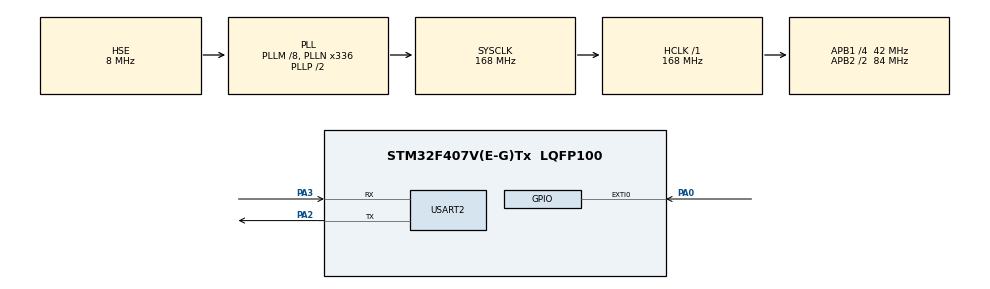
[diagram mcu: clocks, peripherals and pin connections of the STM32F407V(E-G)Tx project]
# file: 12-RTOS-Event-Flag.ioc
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FREERTOS.Tasks01=Task1,24,128,StartTask1,Default,NULL,Dynamic,NULL,NULL;Task02,24,128,StartTask02,Default,NULL,Dynamic,NULL,NULL;Task03,24,128,StartTask03,Default,NULL,Dynamic,NULL,NULL
Mcu.Family=STM32F4
Mcu.Name=STM32F407V(E-G)Tx
Mcu.Package=LQFP100
NVIC.EXTI0_IRQn=true\:5\:0\:true\:false\:true\:true\:true\:true\:true
NVIC.PriorityGroup=NVIC_PRIORITYGROUP_4
NVIC.TIM4_IRQn=true\:15\:0\:false\:false\:true\:false\:false\:true\:true
NVIC.TimeBase=TIM4_IRQn
NVIC.TimeBaseIP=TIM4
PA0-WKUP.Signal=GPXTI0
PA2.Mode=Asynchronous
PA2.Signal=USART2_TX
PA3.Mode=Asynchronous
PA3.Signal=USART2_RX
PH0-OSC_IN.Mode=HSE-External-Oscillator
PH0-OSC_IN.Signal=RCC_OSC_IN
PH1-OSC_OUT.Mode=HSE-External-Oscillator
PH1-OSC_OUT.Signal=RCC_OSC_OUT
ProjectManager.HeapSize=0x200
ProjectManager.StackSize=0x400
ProjectManager.TargetToolchain=STM32CubeIDE
RCC.48MHZClocksFreq_Value=48000000
RCC.AHBFreq_Value=168000000
RCC.APB1CLKDivider=RCC_HCLK_DIV4
RCC.APB1Freq_Value=42000000
RCC.APB1TimFreq_Value=84000000
RCC.APB2CLKDivider=RCC_HCLK_DIV2
RCC.APB2Freq_Value=84000000
RCC.APB2TimFreq_Value=168000000
RCC.CortexFreq_Value=168000000
RCC.HCLKFreq_Value=168000000
RCC.HSE_VALUE=8000000
RCC.HSI_VALUE=16000000
RCC.PLLM=8
RCC.PLLN=336
RCC.PLLQ=7
RCC.PLLSourceVirtual=RCC_PLLSOURCE_HSE
RCC.SYSCLKFreq_VALUE=168000000
RCC.SYSCLKSource=RCC_SYSCLKSOURCE_PLLCLK
RCC.VCOOutputFreq_Value=336000000
USART2.VirtualMode=VM_ASYNC
VP_FREERTOS_VS_CMSIS_V2.Mode=CMSIS_V2
VP_SYS_VS_tim4.Mode=TIM4
board=STM32F407G-DISC1

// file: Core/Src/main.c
/* USER CODE BEGIN Header */
/**
  ******************************************************************************
  * @file           : main.c
  * @brief          : Main program body
  ******************************************************************************
  * @attention
  *
  * Copyright (c) 2026 STMicroelectronics.
  * All rights reserved.
  *
  * This software is licensed under terms that can be found in the LICENSE file
  * in the root directory of this software component.
  * If no LICENSE file comes with this software, it is provided AS-IS.
  *
  ******************************************************************************
  */
/* USER CODE END Header */
#include "main.h"
#include "cmsis_os.h"

/* USER CODE BEGIN Includes */
#include "stdio.h"
#include "string.h"
/* USER CODE END Includes */

UART_HandleTypeDef huart2;

/* Definitions for Task1 */
osThreadId_t Task1Handle;
const osThreadAttr_t Task1_attributes = {
  .name = "Task1",
  .stack_size = 128 * 4,
  .priority = (osPriority_t) osPriorityNormal,
};
/* Definitions for Task02 */
osThreadId_t Task02Handle;
const osThreadAttr_t Task02_attributes = {
  .name = "Task02",
  .stack_size = 128 * 4,
  .priority = (osPriority_t) osPriorityNormal,
};
/* Definitions for Task03 */
osThreadId_t Task03Handle;
const osThreadAttr_t Task03_attributes = {
  .name = "Task03",
  .stack_size = 128 * 4,
  .priority = (osPriority_t) osPriorityNormal,
};
/* USER CODE BEGIN PV */
osEventFlagsId_t EventGroup;
/* USER CODE END PV */

void SystemClock_Config(void);
static void MX_GPIO_Init(void);
static void MX_USART2_UART_Init(void);
void StartTask1(void *argument);
void StartTask02(void *argument);
void StartTask03(void *argument);

/* USER CODE BEGIN 0 */
//int _write(int file, char *ptr, int len){
//	HAL_UART_Transmit(&huart2, (uint8_t*)ptr, len, HAL_MAX_DELAY);
//	return len;
//}

int _write(int file,char *ptr,int len)
{
	int i = 0;
	for(i=0;i<len;i++)
	{
		ITM_SendChar((*ptr++));
	}
	return len;
}
/* USER CODE END 0 */

int main(void)
{

  /* MCU Configuration--------------------------------------------------------*/

  /* Reset of all peripherals, Initializes the Flash interface and the Systick. */
  HAL_Init();

  /* Configure the system clock */
  SystemClock_Config();

  /* Initialize all configured peripherals */
  MX_GPIO_Init();
  MX_USART2_UART_Init();

  /* Init scheduler */
  osKernelInitialize();

  /* Create the thread(s) */
  /* creation of Task1 */
  Task1Handle = osThreadNew(StartTask1, NULL, &Task1_attributes);

  /* creation of Task02 */
  Task02Handle = osThreadNew(StartTask02, NULL, &Task02_attributes);

  /* creation of Task03 */
  Task03Handle = osThreadNew(StartTask03, NULL, &Task03_attributes);

  /* USER CODE BEGIN RTOS_THREADS */
  /* add threads, ... */
  EventGroup = osEventFlagsNew(NULL);
  /* USER CODE END RTOS_THREADS */

  /* Start scheduler */
  osKernelStart();

  /* We should never get here as control is now taken by the scheduler */

  /* Infinite loop */
  while (1)
  {

  }
}

void SystemClock_Config(void)
{
  RCC_OscInitTypeDef RCC_OscInitStruct = {0};
  RCC_ClkInitTypeDef RCC_ClkInitStruct = {0};

  /** Configure the main internal regulator output voltage
  */
  __HAL_RCC_PWR_CLK_ENABLE();
  __HAL_PWR_VOLTAGESCALING_CONFIG(PWR_REGULATOR_VOLTAGE_SCALE1);

  /** Initializes the RCC Oscillators according to the specified parameters
  * in the RCC_OscInitTypeDef structure.
  */
  RCC_OscInitStruct.OscillatorType = RCC_OSCILLATORTYPE_HSE;
  RCC_OscInitStruct.HSEState = RCC_HSE_ON;
  RCC_OscInitStruct.PLL.PLLState = RCC_PLL_ON;
  RCC_OscInitStruct.PLL.PLLSource = RCC_PLLSOURCE_HSE;
  RCC_OscInitStruct.PLL.PLLM = 8;
  RCC_OscInitStruct.PLL.PLLN = 336;
  RCC_OscInitStruct.PLL.PLLP = RCC_PLLP_DIV2;
  RCC_OscInitStruct.PLL.PLLQ = 7;
  if (HAL_RCC_OscConfig(&RCC_OscInitStruct) != HAL_OK)
  {
    Error_Handler();
  }

  /** Initializes the CPU, AHB and APB buses clocks
  */
  RCC_ClkInitStruct.ClockType = RCC_CLOCKTYPE_HCLK|RCC_CLOCKTYPE_SYSCLK
                              |RCC_CLOCKTYPE_PCLK1|RCC_CLOCKTYPE_PCLK2;
  RCC_ClkInitStruct.SYSCLKSource = RCC_SYSCLKSOURCE_PLLCLK;
  RCC_ClkInitStruct.AHBCLKDivider = RCC_SYSCLK_DIV1;
  RCC_ClkInitStruct.APB1CLKDivider = RCC_HCLK_DIV4;
  RCC_ClkInitStruct.APB2CLKDivider = RCC_HCLK_DIV2;

  if (HAL_RCC_ClockConfig(&RCC_ClkInitStruct, FLASH_LATENCY_5) != HAL_OK)
  {
    Error_Handler();
  }
}

static void MX_USART2_UART_Init(void)
{

  huart2.Instance = USART2;
  huart2.Init.BaudRate = 115200;
  huart2.Init.WordLength = UART_WORDLENGTH_8B;
  huart2.Init.StopBits = UART_STOPBITS_1;
  huart2.Init.Parity = UART_PARITY_NONE;
  huart2.Init.Mode = UART_MODE_TX_RX;
  huart2.Init.HwFlowCtl = UART_HWCONTROL_NONE;
  huart2.Init.OverSampling = UART_OVERSAMPLING_16;
  if (HAL_UART_Init(&huart2) != HAL_OK)
  {
    Error_Handler();
  }

}

static void MX_GPIO_Init(void)
{
  GPIO_InitTypeDef GPIO_InitStruct = {0};

  /* GPIO Ports Clock Enable */
  __HAL_RCC_GPIOH_CLK_ENABLE();
  __HAL_RCC_GPIOA_CLK_ENABLE();

  /*Configure GPIO pin : PA0 */
  GPIO_InitStruct.Pin = GPIO_PIN_0;
  GPIO_InitStruct.Mode = GPIO_MODE_IT_RISING;
  GPIO_InitStruct.Pull = GPIO_NOPULL;
  HAL_GPIO_Init(GPIOA, &GPIO_InitStruct);

  /* EXTI interrupt init*/
  HAL_NVIC_SetPriority(EXTI0_IRQn, 5, 0);
  HAL_NVIC_EnableIRQ(EXTI0_IRQn);

}

/* USER CODE BEGIN 4 */
void HAL_GPIO_EXIT_Callback(uint16_t GPIO_Pin){
	osEventFlagsSet(EventGroup, 0x50);
	printf("Task interrupt\n");
}
/* USER CODE END 4 */

void StartTask1(void *argument)
{
  /* USER CODE BEGIN 5 */
  /* Infinite loop */
  for(;;)
  {
	  osEventFlagsWait(EventGroup, 0x51, osFlagsWaitAll, osWaitForever);
	  printf("Task 1\n");
   // osDelay(1);
  }
  /* USER CODE END 5 */
}

void StartTask02(void *argument)
{
  /* USER CODE BEGIN StartTask02 */
  /* Infinite loop */
  for(;;)
  {
	  osEventFlagsSet(EventGroup, 1);
	  printf("Task 2\n");
	  osDelay(3000);
  }
  /* USER CODE END StartTask02 */
}

void StartTask03(void *argument)
{
  /* USER CODE BEGIN StartTask03 */
  /* Infinite loop */
  for(;;)
  {
	  osEventFlagsWait(EventGroup, 0x51, osFlagsWaitAll, osWaitForever);
	  printf("Task 3\n");
	  //osDelay(1);
  }
  /* USER CODE END StartTask03 */
}

void HAL_TIM_PeriodElapsedCallback(TIM_HandleTypeDef *htim)
{
  if (htim->Instance == TIM4)
  {
    HAL_IncTick();
  }
}

void Error_Handler(void)
{
  __disable_irq();
  while (1)
  {
  }
}
